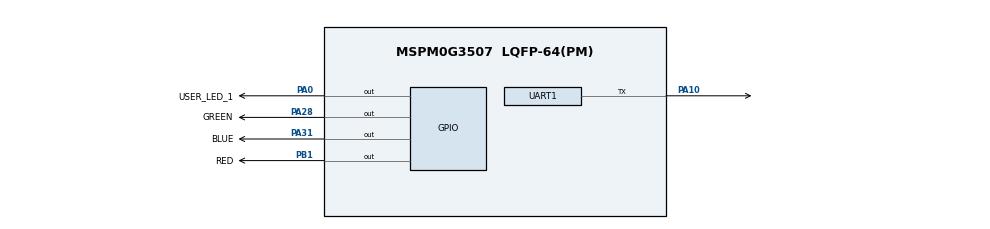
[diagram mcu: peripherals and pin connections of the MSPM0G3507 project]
//@cliArgs --device "MSPM0G350X" --package "LQFP-64(PM)" --part "Default"
//@v2CliArgs --device "MSPM0G3507" --package "LQFP-64(PM)"
// @cliArgs --board /ti/boards/LP_MSPM0G3507 --rtos nortos

/**
 * Import the modules used in this configuration.
 */
const ADC12  = scripting.addModule("/ti/driverlib/ADC12", {}, false);
const ADC121 = ADC12.addInstance();
const ADC122 = ADC12.addInstance();
const Board  = scripting.addModule("/ti/driverlib/Board");
const GPIO   = scripting.addModule("/ti/driverlib/GPIO", {}, false);
const GPIO1  = GPIO.addInstance();
const GPIO2  = GPIO.addInstance();
const GPIO3  = GPIO.addInstance();
const GPIO4  = GPIO.addInstance();
const SYSCTL = scripting.addModule("/ti/driverlib/SYSCTL");
const UART   = scripting.addModule("/ti/driverlib/UART", {}, false);
const UART1  = UART.addInstance();

/**
 * Write custom configuration values to the imported modules.
 */
ADC121.$name                      = "ADC12_0";
ADC121.sampClkSrc                 = "DL_ADC12_CLOCK_ULPCLK";
ADC121.sampClkDiv                 = "DL_ADC12_CLOCK_DIVIDE_8";
ADC121.adcMem0chansel             = "DL_ADC12_INPUT_CHAN_7";
ADC121.sampleTime0                = "125 us";
ADC121.enabledInterrupts          = [];
ADC121.powerDownMode              = "DL_ADC12_POWER_DOWN_MODE_MANUAL";
ADC121.peripheral.$assign         = "ADC0";
ADC121.peripheral.adcPin7.$assign = "PA22";

GPIO1.$name                         = "GPIO_LEDS";
GPIO1.port                          = "PORTA";
GPIO1.portSegment                   = "Lower";
GPIO1.associatedPins[0].$name       = "USER_LED_1";
GPIO1.associatedPins[0].assignedPin = "0";
GPIO1.associatedPins[0].pin.$assign = "PA0";

GPIO2.$name                         = "BOOST_RGB_G";
GPIO2.port                          = "PORTA";
GPIO2.portSegment                   = "Upper";
GPIO2.associatedPins[0].$name       = "GREEN";
GPIO2.associatedPins[0].assignedPin = "28";
GPIO2.associatedPins[0].pin.$assign = "PA28";
GPIO3.$name                         = "BOOST_RGB_B";
GPIO3.port                          = "PORTA";
GPIO3.portSegment                   = "Upper";
GPIO3.associatedPins[0].$name       = "BLUE";
GPIO3.associatedPins[0].assignedPin = "31";
GPIO3.associatedPins[0].pin.$assign = "PA31";

GPIO4.$name                         = "BOOST_RGB_R";
GPIO4.port                          = "PORTB";
GPIO4.portSegment                   = "Lower";
GPIO4.associatedPins[0].$name       = "RED";
GPIO4.associatedPins[0].assignedPin = "1";
GPIO4.associatedPins[0].pin.$assign = "PB1";

UART1.$name                    = "UART_0";
UART1.enableFIFO               = true;
UART1.targetBaudRate           = 115200;
UART1.rxFifoThreshold          = "DL_UART_RX_FIFO_LEVEL_ONE_ENTRY";
UART1.txFifoThreshold          = "DL_UART_TX_FIFO_LEVEL_3_4_EMPTY";
UART1.direction                = "TX";
UART1.peripheral.$assign       = "UART0";
UART1.peripheral.txPin.$assign = "PA10";

SYSCTL.forceDefaultClkConfig = true;

// Accelerometer X: BoosterPack pin 23 -> PB19 -> ADC1 channel 6.
// Accelerometer Z (PB18, ADC1 channel 5) is MEM1, configured in main.c.
ADC122.$name                       = "ADC12_1";
ADC122.sampClkSrc                  = "DL_ADC12_CLOCK_ULPCLK";
ADC122.sampClkDiv                  = "DL_ADC12_CLOCK_DIVIDE_8";
ADC122.adcMem0chansel              = "DL_ADC12_INPUT_CHAN_6";
ADC122.sampleTime0                 = "125 us";
ADC122.enabledInterrupts           = [];
ADC122.powerDownMode               = "DL_ADC12_POWER_DOWN_MODE_MANUAL";
ADC122.peripheral.$assign          = "ADC1";
ADC122.peripheral.adcPin6.$assign  = "PB19";
